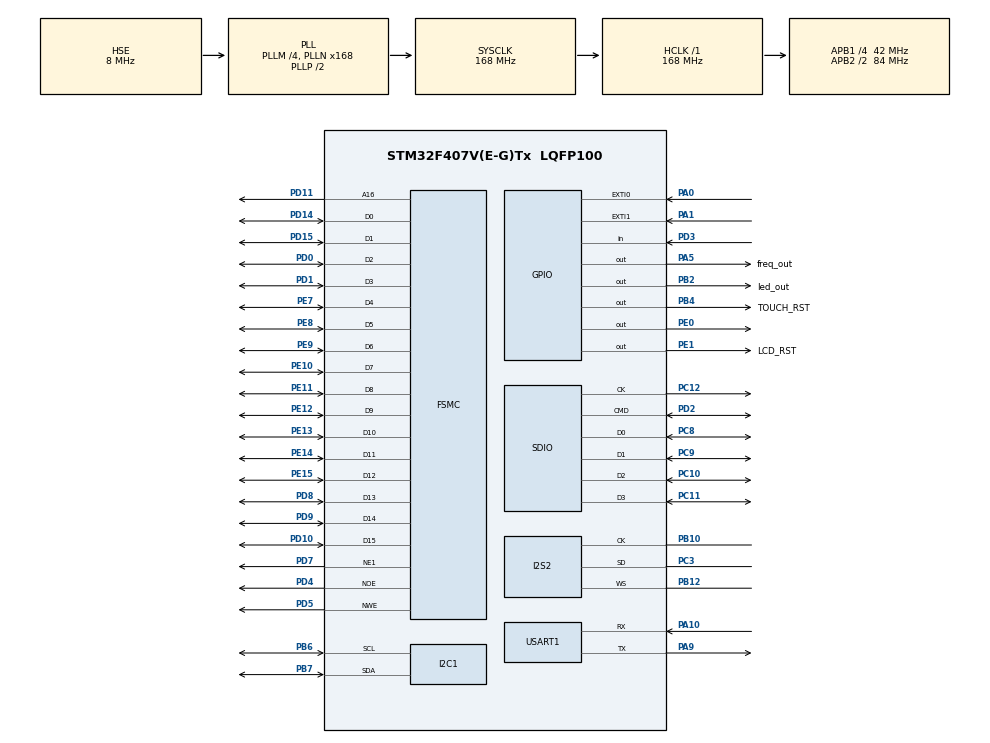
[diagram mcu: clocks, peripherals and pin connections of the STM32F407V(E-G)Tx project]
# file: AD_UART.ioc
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Dma.MEMTOMEM.2.Direction=DMA_MEMORY_TO_MEMORY
Dma.MEMTOMEM.2.FIFOMode=DMA_FIFOMODE_ENABLE
Dma.MEMTOMEM.2.FIFOThreshold=DMA_FIFO_THRESHOLD_FULL
Dma.MEMTOMEM.2.Instance=DMA2_Stream0
Dma.MEMTOMEM.2.MemBurst=DMA_MBURST_SINGLE
Dma.MEMTOMEM.2.MemDataAlignment=DMA_MDATAALIGN_BYTE
Dma.MEMTOMEM.2.MemInc=DMA_MINC_DISABLE
Dma.MEMTOMEM.2.Mode=DMA_NORMAL
Dma.MEMTOMEM.2.PeriphBurst=DMA_PBURST_SINGLE
Dma.MEMTOMEM.2.PeriphDataAlignment=DMA_PDATAALIGN_BYTE
Dma.MEMTOMEM.2.PeriphInc=DMA_PINC_ENABLE
Dma.MEMTOMEM.2.Priority=DMA_PRIORITY_MEDIUM
Dma.Request0=SPI2_TX
Dma.Request1=SDIO_RX
Dma.Request2=MEMTOMEM
Dma.Request3=SDIO_TX
Dma.SDIO_RX.1.Direction=DMA_PERIPH_TO_MEMORY
Dma.SDIO_RX.1.FIFOMode=DMA_FIFOMODE_ENABLE
Dma.SDIO_RX.1.FIFOThreshold=DMA_FIFO_THRESHOLD_FULL
Dma.SDIO_RX.1.Instance=DMA2_Stream3
Dma.SDIO_RX.1.MemBurst=DMA_MBURST_INC4
Dma.SDIO_RX.1.MemDataAlignment=DMA_MDATAALIGN_WORD
Dma.SDIO_RX.1.MemInc=DMA_MINC_ENABLE
Dma.SDIO_RX.1.Mode=DMA_PFCTRL
Dma.SDIO_RX.1.PeriphBurst=DMA_PBURST_INC4
Dma.SDIO_RX.1.PeriphDataAlignment=DMA_PDATAALIGN_WORD
Dma.SDIO_RX.1.PeriphInc=DMA_PINC_DISABLE
Dma.SDIO_RX.1.Priority=DMA_PRIORITY_HIGH
Dma.SDIO_TX.3.Direction=DMA_MEMORY_TO_PERIPH
Dma.SDIO_TX.3.FIFOMode=DMA_FIFOMODE_ENABLE
Dma.SDIO_TX.3.FIFOThreshold=DMA_FIFO_THRESHOLD_FULL
Dma.SDIO_TX.3.Instance=DMA2_Stream6
Dma.SDIO_TX.3.MemBurst=DMA_MBURST_INC4
Dma.SDIO_TX.3.MemDataAlignment=DMA_MDATAALIGN_WORD
Dma.SDIO_TX.3.MemInc=DMA_MINC_ENABLE
Dma.SDIO_TX.3.Mode=DMA_PFCTRL
Dma.SDIO_TX.3.PeriphBurst=DMA_PBURST_INC4
Dma.SDIO_TX.3.PeriphDataAlignment=DMA_PDATAALIGN_WORD
Dma.SDIO_TX.3.PeriphInc=DMA_PINC_DISABLE
Dma.SDIO_TX.3.Priority=DMA_PRIORITY_HIGH
Dma.SPI2_TX.0.Direction=DMA_MEMORY_TO_PERIPH
Dma.SPI2_TX.0.FIFOMode=DMA_FIFOMODE_DISABLE
Dma.SPI2_TX.0.Instance=DMA1_Stream4
Dma.SPI2_TX.0.MemDataAlignment=DMA_MDATAALIGN_HALFWORD
Dma.SPI2_TX.0.MemInc=DMA_MINC_ENABLE
Dma.SPI2_TX.0.Mode=DMA_NORMAL
Dma.SPI2_TX.0.PeriphDataAlignment=DMA_PDATAALIGN_HALFWORD
Dma.SPI2_TX.0.PeriphInc=DMA_PINC_DISABLE
Dma.SPI2_TX.0.Priority=DMA_PRIORITY_HIGH
FATFS.BSP.number=1
FATFS.USE_DMA_CODE_SD=0
FATFS._CODE_PAGE=936
FATFS._FS_LOCK=2
FATFS._FS_READONLY=0
FATFS._STRF_ENCODE=0
FATFS._USE_FASTSEEK=1
FATFS._USE_LFN=2
FATFS._USE_MKFS=0
FATFS._USE_MUTEX=0
FATFS0.BSP.STBoard=false
FATFS0.BSP.api=Unknown
FATFS0.BSP.instance=PD3
FATFS0.BSP.ip=GPIO
FATFS0.BSP.mode=Input
FATFS0.BSP.name=Detect_SDIO
FATFS0.BSP.solution=PD3
FREERTOS.Tasks01=defaultTask,24,128,StartDefaultTask,Default,NULL,Dynamic,NULL,NULL
FREERTOS.configENABLE_FPU=1
FREERTOS.configTOTAL_HEAP_SIZE=32768
FSMC.AddressSetupTime1=1
FSMC.BusTurnAroundDuration1=0
FSMC.DataSetupTime1=4
FSMC.ExtendedAddressSetupTime1=1
FSMC.ExtendedBusTurnAroundDuration1=0
FSMC.ExtendedDataSetupTime1=5
FSMC.ExtendedMode1=FSMC_EXTENDED_MODE_ENABLE
I2S2.AudioFreq=AudioFreqCustomValue
I2S2.AudioFreqCustom=44100
I2S2.ErrorAudioFreq=0.13 %
I2S2.FullDuplexMode=I2S_FULLDUPLEXMODE_DISABLE
I2S2.Instance=SPI$Index
I2S2.RealAudioFreq=44.061 KHz
I2S2.VirtualMode=I2S_MODE_MASTER
Mcu.Family=STM32F4
Mcu.Name=STM32F407V(E-G)Tx
Mcu.Package=LQFP100
NVIC.DMA1_Stream4_IRQn=true\:5\:0\:false\:false\:true\:true\:false\:true\:true
NVIC.DMA2_Stream3_IRQn=true\:5\:0\:false\:false\:true\:true\:false\:true\:true
NVIC.DMA2_Stream6_IRQn=true\:5\:0\:false\:false\:true\:true\:false\:true\:true
NVIC.EXTI0_IRQn=true\:5\:0\:false\:false\:true\:true\:true\:true\:true
NVIC.EXTI1_IRQn=true\:5\:0\:false\:false\:true\:true\:true\:true\:true
NVIC.PriorityGroup=NVIC_PRIORITYGROUP_4
NVIC.SDIO_IRQn=true\:7\:0\:true\:false\:true\:true\:true\:true\:true
NVIC.SPI2_IRQn=true\:6\:0\:true\:false\:true\:true\:true\:true\:true
NVIC.TIM8_TRG_COM_TIM14_IRQn=true\:15\:0\:false\:false\:true\:false\:false\:true\:true
NVIC.TimeBase=TIM8_TRG_COM_TIM14_IRQn
NVIC.TimeBaseIP=TIM14
PA0-WKUP.GPIO_PuPd=GPIO_PULLUP
PA0-WKUP.Signal=GPXTI0
PA1.GPIO_PuPd=GPIO_PULLUP
PA1.Signal=GPXTI1
PA10.Mode=Asynchronous
PA10.Signal=USART1_RX
PA13.Mode=Serial_Wire
PA13.Signal=SYS_JTMS-SWDIO
PA14.Mode=Serial_Wire
PA14.Signal=SYS_JTCK-SWCLK
PA5.GPIO_Label=freq_out
PA5.Signal=GPIO_Output
PA9.Mode=Asynchronous
PA9.Signal=USART1_TX
PB10.GPIO_Speed=GPIO_SPEED_FREQ_VERY_HIGH
PB10.Mode=Half_Duplex_Master
PB10.Signal=I2S2_CK
PB12.GPIO_Speed=GPIO_SPEED_FREQ_VERY_HIGH
PB12.Mode=Half_Duplex_Master
PB12.Signal=I2S2_WS
PB2.GPIO_Label=led_out
PB2.Signal=GPIO_Output
PB4.GPIO_Label=TOUCH_RST
PB4.Signal=GPIO_Output
PB6.Mode=I2C
PB6.Signal=I2C1_SCL
PB7.Mode=I2C
PB7.Signal=I2C1_SDA
PC10.Mode=SD_4_bits_Wide_bus
PC10.Signal=SDIO_D2
PC11.Mode=SD_4_bits_Wide_bus
PC11.Signal=SDIO_D3
PC12.Mode=SD_4_bits_Wide_bus
PC12.Signal=SDIO_CK
PC14-OSC32_IN.Mode=LSE-External-Oscillator
PC14-OSC32_IN.Signal=RCC_OSC32_IN
PC15-OSC32_OUT.Mode=LSE-External-Oscillator
PC15-OSC32_OUT.Signal=RCC_OSC32_OUT
PC3.GPIO_Speed=GPIO_SPEED_FREQ_VERY_HIGH
PC3.Mode=Half_Duplex_Master
PC3.Signal=I2S2_SD
PC8.Mode=SD_4_bits_Wide_bus
PC8.Signal=SDIO_D0
PC9.Mode=SD_4_bits_Wide_bus
PC9.Signal=SDIO_D1
PD0.Mode=16b-d1
PD0.Signal=FSMC_D2
PD1.Mode=16b-d1
PD1.Signal=FSMC_D3
PD10.Mode=16b-d1
PD10.Signal=FSMC_D15
PD11.Mode=A16_1
PD11.Signal=FSMC_A16
PD14.Mode=16b-d1
PD14.Signal=FSMC_D0
PD15.Mode=16b-d1
PD15.Signal=FSMC_D1
PD2.Mode=SD_4_bits_Wide_bus
PD2.Signal=SDIO_CMD
PD3.Signal=GPIO_Input
PD4.Mode=Lcd1
PD4.Signal=FSMC_NOE
PD5.Mode=Lcd1
PD5.Signal=FSMC_NWE
PD7.Mode=NorPsramChipSelect1_1
PD7.Signal=FSMC_NE1
PD8.Mode=16b-d1
PD8.Signal=FSMC_D13
PD9.Mode=16b-d1
PD9.Signal=FSMC_D14
PE0.GPIO_Speed=GPIO_SPEED_FREQ_VERY_HIGH
PE0.PinState=GPIO_PIN_SET
PE0.Signal=GPIO_Output
PE1.GPIO_Label=LCD_RST
PE1.Signal=GPIO_Output
PE10.Mode=16b-d1
PE10.Signal=FSMC_D7
PE11.Mode=16b-d1
PE11.Signal=FSMC_D8
PE12.Mode=16b-d1
PE12.Signal=FSMC_D9
PE13.Mode=16b-d1
PE13.Signal=FSMC_D10
PE14.Mode=16b-d1
PE14.Signal=FSMC_D11
PE15.Mode=16b-d1
PE15.Signal=FSMC_D12
PE7.Mode=16b-d1
PE7.Signal=FSMC_D4
PE8.Mode=16b-d1
PE8.Signal=FSMC_D5
PE9.Mode=16b-d1
PE9.Signal=FSMC_D6
PH0-OSC_IN.Mode=HSE-External-Oscillator
PH0-OSC_IN.Signal=RCC_OSC_IN
PH1-OSC_OUT.Mode=HSE-External-Oscillator
PH1-OSC_OUT.Signal=RCC_OSC_OUT
ProjectManager.HeapSize=0x200
ProjectManager.StackSize=0x400
ProjectManager.TargetToolchain=MDK-ARM V5.32
RCC.48MHZClocksFreq_Value=48000000
RCC.AHBFreq_Value=168000000
RCC.APB1CLKDivider=RCC_HCLK_DIV4
RCC.APB1Freq_Value=42000000
RCC.APB1TimFreq_Value=84000000
RCC.APB2CLKDivider=RCC_HCLK_DIV2
RCC.APB2Freq_Value=84000000
RCC.APB2TimFreq_Value=168000000
RCC.CortexFreq_Value=168000000
RCC.HCLKFreq_Value=168000000
RCC.HSE_VALUE=8000000
RCC.HSI_VALUE=16000000
RCC.PLLI2SN=184
RCC.PLLI2SR=3
RCC.PLLM=4
RCC.PLLN=168
RCC.PLLQ=7
RCC.PLLSourceVirtual=RCC_PLLSOURCE_HSE
RCC.SYSCLKFreq_VALUE=168000000
RCC.SYSCLKSource=RCC_SYSCLKSOURCE_PLLCLK
RCC.VCOOutputFreq_Value=336000000
SDIO.HardwareFlowControl=SDIO_HARDWARE_FLOW_CONTROL_DISABLE
TIM1.AutoReloadPreload=TIM_AUTORELOAD_PRELOAD_ENABLE
TIM1.ClockDivision=TIM_CLOCKDIVISION_DIV4
TIM1.Period=5000-1
TIM1.Prescaler=840-1
TIM2.AutoReloadPreload=TIM_AUTORELOAD_PRELOAD_ENABLE
TIM2.ClockDivision=TIM_CLOCKDIVISION_DIV4
TIM2.Period=1
TIM2.Prescaler=840-1
TIM2.TIM_MasterOutputTrigger=TIM_TRGO_UPDATE
TIM2.TIM_MasterSlaveMode=TIM_MASTERSLAVEMODE_DISABLE
USART1.VirtualMode=VM_ASYNC
VP_FATFS_VS_SDIO.Mode=SDIO
VP_FREERTOS_VS_CMSIS_V2.Mode=CMSIS_V2
VP_SYS_VS_tim14.Mode=TIM14
VP_TIM1_VS_ClockSourceINT.Mode=Internal
VP_TIM2_VS_ClockSourceINT.Mode=Internal
board=custom

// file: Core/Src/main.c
/* USER CODE BEGIN Header */
/**
  ******************************************************************************
  * @file           : main.c
  * @brief          : Main program body
  ******************************************************************************
  * @attention
  *
  * Copyright (c) 2024 STMicroelectronics.
  * All rights reserved.
  *
  * This software is licensed under terms that can be found in the LICENSE file
  * in the root directory of this software component.
  * If no LICENSE file comes with this software, it is provided AS-IS.
  *
  ******************************************************************************
  */
/* USER CODE END Header */
#include "main.h"
#include "cmsis_os.h"
#include "dma.h"
#include "fatfs.h"
#include "i2c.h"
#include "i2s.h"
#include "sdio.h"
#include "tim.h"
#include "usart.h"
#include "gpio.h"
#include "fsmc.h"

/* USER CODE BEGIN Includes */
#include <stdio.h>
#include "string.h"

/* USER CODE END Includes */

void SystemClock_Config(void);
void MX_FREERTOS_Init(void);

int main(void)
{

  /* MCU Configuration--------------------------------------------------------*/

  /* Reset of all peripherals, Initializes the Flash interface and the Systick. */
  HAL_Init();

  /* Configure the system clock */
  SystemClock_Config();

  /* Initialize all configured peripherals */
  MX_GPIO_Init();
  MX_DMA_Init();
  MX_TIM1_Init();
  MX_TIM2_Init();
  MX_USART1_UART_Init();
  MX_SDIO_SD_Init();
  MX_FATFS_Init();
  MX_I2S2_Init();
  MX_FSMC_Init();
  MX_I2C1_Init();
  /* USER CODE BEGIN 2 */

  //app_main();

  /* USER CODE END 2 */

  /* Init scheduler */
  osKernelInitialize();  /* Call init function for freertos objects (in cmsis_os2.c) */
  MX_FREERTOS_Init();

  /* Start scheduler */
  osKernelStart();

  /* We should never get here as control is now taken by the scheduler */

  /* Infinite loop */
  while (1)
  {

  }
}

void SystemClock_Config(void)
{
  RCC_OscInitTypeDef RCC_OscInitStruct = {0};
  RCC_ClkInitTypeDef RCC_ClkInitStruct = {0};

  /** Configure the main internal regulator output voltage
  */
  __HAL_RCC_PWR_CLK_ENABLE();
  __HAL_PWR_VOLTAGESCALING_CONFIG(PWR_REGULATOR_VOLTAGE_SCALE1);

  /** Initializes the RCC Oscillators according to the specified parameters
  * in the RCC_OscInitTypeDef structure.
  */
  RCC_OscInitStruct.OscillatorType = RCC_OSCILLATORTYPE_HSE;
  RCC_OscInitStruct.HSEState = RCC_HSE_ON;
  RCC_OscInitStruct.PLL.PLLState = RCC_PLL_ON;
  RCC_OscInitStruct.PLL.PLLSource = RCC_PLLSOURCE_HSE;
  RCC_OscInitStruct.PLL.PLLM = 4;
  RCC_OscInitStruct.PLL.PLLN = 168;
  RCC_OscInitStruct.PLL.PLLP = RCC_PLLP_DIV2;
  RCC_OscInitStruct.PLL.PLLQ = 7;
  if (HAL_RCC_OscConfig(&RCC_OscInitStruct) != HAL_OK)
  {
    Error_Handler();
  }

  /** Initializes the CPU, AHB and APB buses clocks
  */
  RCC_ClkInitStruct.ClockType = RCC_CLOCKTYPE_HCLK|RCC_CLOCKTYPE_SYSCLK
                              |RCC_CLOCKTYPE_PCLK1|RCC_CLOCKTYPE_PCLK2;
  RCC_ClkInitStruct.SYSCLKSource = RCC_SYSCLKSOURCE_PLLCLK;
  RCC_ClkInitStruct.AHBCLKDivider = RCC_SYSCLK_DIV1;
  RCC_ClkInitStruct.APB1CLKDivider = RCC_HCLK_DIV4;
  RCC_ClkInitStruct.APB2CLKDivider = RCC_HCLK_DIV2;

  if (HAL_RCC_ClockConfig(&RCC_ClkInitStruct, FLASH_LATENCY_5) != HAL_OK)
  {
    Error_Handler();
  }
}

void HAL_TIM_PeriodElapsedCallback(TIM_HandleTypeDef *htim)
{
  if (htim->Instance == TIM14)
  {
    HAL_IncTick();
  }
}

void Error_Handler(void)
{
  /* USER CODE BEGIN Error_Handler_Debug */
  /* User can add his own implementation to report the HAL error return state */
  volatile uint32_t delay;

  __disable_irq();
  while (1)
  {
    HAL_GPIO_TogglePin(led_out_GPIO_Port, led_out_Pin);
    for (delay = 0; delay < 300000U; delay++)
    {
      __NOP();
    }
  }
  /* USER CODE END Error_Handler_Debug */
}

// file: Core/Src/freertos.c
/* USER CODE BEGIN Header */
/**
  ******************************************************************************
  * File Name          : freertos.c
  * Description        : Code for freertos applications
  ******************************************************************************
  * @attention
  *
  * Copyright (c) 2026 STMicroelectronics.
  * All rights reserved.
  *
  * This software is licensed under terms that can be found in the LICENSE file
  * in the root directory of this software component.
  * If no LICENSE file comes with this software, it is provided AS-IS.
  *
  ******************************************************************************
  */
/* USER CODE END Header */

#include "FreeRTOS.h"
#include "task.h"
#include "main.h"
#include "cmsis_os.h"

/* USER CODE BEGIN Includes */
#include "../../SRC/audio_app.h"
/* USER CODE END Includes */

/* Definitions for defaultTask */
osThreadId_t defaultTaskHandle;
const osThreadAttr_t defaultTask_attributes = {
  .name = "defaultTask",
  .stack_size = 128 * 4,
  .priority = (osPriority_t) osPriorityNormal,
};

void StartDefaultTask(void *argument);

void MX_FREERTOS_Init(void); /* (MISRA C 2004 rule 8.1) */

void MX_FREERTOS_Init(void) {

  /* Create the thread(s) */
  /* 本轮不使用 defaultTask，改为 4 任务流水线：
   * 1. SD 预读取任务
   * 2. 解码任务
   * 3. 播放任务
   * 4. LVGL 显示任务
   */

  /* USER CODE BEGIN RTOS_THREADS */
  AudioApp_CreateTasks();
  /* USER CODE END RTOS_THREADS */

}

void StartDefaultTask(void *argument)
{
  /* USER CODE BEGIN StartDefaultTask */
  (void)argument;
  for(;;)
  {
    osDelay(1000);
  }
  /* USER CODE END StartDefaultTask */
}
